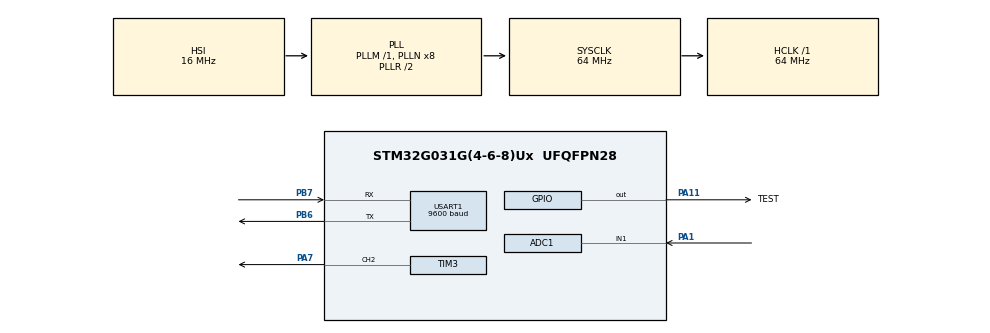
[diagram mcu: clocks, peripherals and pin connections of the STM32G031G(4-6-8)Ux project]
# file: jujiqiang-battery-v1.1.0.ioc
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Mcu.Family=STM32G0
NVIC.TIM14_IRQn=true\:0\:0\:false\:false\:true\:true\:true
RCC.CortexFreq_Value=64000000
ADC1.Rank-0\#ChannelRegularConversion=1
Dma.TIM3_CH2.0.Mode=DMA_NORMAL
PA11\ [PA9].GPIO_Label=TEST
USART1.BaudRate=9600
PA14-BOOT0.Mode=Serial_Wire
Dma.TIM3_CH2.0.PeriphInc=DMA_PINC_DISABLE
RCC.EXTERNAL_CLOCK_VALUE=12288000
Dma.TIM3_CH2.0.Instance=DMA1_Channel1
Dma.TIM3_CH2.0.EventEnable=DISABLE
RCC.SYSCLKSource=RCC_SYSCLKSOURCE_PLLCLK
ProjectManager.StackSize=0x400
Dma.TIM3_CH2.0.Direction=DMA_MEMORY_TO_PERIPH
USART1.VirtualMode-Asynchronous=VM_ASYNC
PA13.Signal=SYS_SWDIO
Dma.TIM3_CH2.0.SyncPolarity=HAL_DMAMUX_SYNC_NO_EVENT
ProjectManager.TargetToolchain=STM32CubeIDE
Dma.TIM3_CH2.0.PeriphDataAlignment=DMA_PDATAALIGN_HALFWORD
RCC.HCLKFreq_Value=64000000
TIM3.Period=79
PB6.Signal=USART1_TX
PA11\ [PA9].GPIO_PuPd=GPIO_PULLUP
PB6.Mode=Asynchronous
RCC.LSE_VALUE=32768
PA1.Signal=ADC1_IN1
PA7.GPIO_PuPd=GPIO_PULLUP
RCC.AHBFreq_Value=64000000
PA14-BOOT0.Signal=SYS_SWCLK
ADC1.Channel-0\#ChannelRegularConversion=ADC_CHANNEL_1
SH.S_TIM3_CH2.0=TIM3_CH2,PWM Generation2 CH2
RCC.HSE_VALUE=8000000
board=custom
RCC.VCOOutputFreq_Value=128000000
TIM14.Period=99
PA7.GPIO_Speed=GPIO_SPEED_FREQ_VERY_HIGH
Dma.TIM3_CH2.0.SyncSignalID=NONE
PA1.Mode=IN1
Dma.TIM3_CH2.0.Priority=DMA_PRIORITY_MEDIUM
Dma.TIM3_CH2.0.MemInc=DMA_MINC_ENABLE
RCC.ADCFreq_Value=64000000
Dma.TIM3_CH2.0.SignalID=NONE
PB7.Signal=USART1_RX
PA13.Mode=Serial_Wire
PA11\ [PA9].Signal=GPIO_Output
Mcu.Name=STM32G031G(4-6-8)Ux
ADC1.SamplingTime-0\#ChannelRegularConversion=ADC_SAMPLINGTIME_COMMON_1
TIM14.Prescaler=639
ADC1.SelectedChannel=ADC_CHANNEL_1
RCC.SYSCLKFreq_VALUE=64000000
Mcu.Package=UFQFPN28
ADC1.master=1
PB7.Mode=Asynchronous
ProjectManager.HeapSize=0x200
Dma.TIM3_CH2.0.MemDataAlignment=DMA_MDATAALIGN_HALFWORD
RCC.HSI_VALUE=16000000
ADC1.NbrOfConversionFlag=1
Dma.TIM3_CH2.0.Polarity=HAL_DMAMUX_REQ_GEN_RISING
Dma.TIM3_CH2.0.SyncRequestNumber=1
TIM3.Channel-PWM\ Generation2\ CH2=TIM_CHANNEL_2
VP_TIM14_VS_ClockSourceINT.Mode=Enable_Timer
Dma.TIM3_CH2.0.RequestNumber=1
NVIC.DMA1_Channel1_IRQn=true\:0\:0\:false\:false\:true\:false\:true
NVIC.USART1_IRQn=true\:0\:0\:false\:false\:true\:true\:true
Dma.Request0=TIM3_CH2
VP_TIM3_VS_ClockSourceINT.Mode=Internal
Dma.TIM3_CH2.0.SyncEnable=DISABLE
PA7.Signal=S_TIM3_CH2

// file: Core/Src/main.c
/* USER CODE BEGIN Header */
/**
  ******************************************************************************
  * @file           : main.c
  * @brief          : Main program body
  ******************************************************************************
  * @attention
  *
  * <h2><center>&copy; Copyright (c) 2021 STMicroelectronics.
  * All rights reserved.</center></h2>
  *
  * This software component is licensed by ST under BSD 3-Clause license,
  * the "License"; You may not use this file except in compliance with the
  * License. You may obtain a copy of the License at:
  *                        opensource.org/licenses/BSD-3-Clause
  *
  ******************************************************************************
  */
/* USER CODE END Header */
#include "main.h"
#include "adc.h"
#include "dma.h"
#include "tim.h"
#include "usart.h"
#include "gpio.h"

/* USER CODE BEGIN Includes */

#include "stdio.h"
#include "S1_main.h"
/* USER CODE END Includes */

void SystemClock_Config(void);

int main(void)
{

  /* MCU Configuration--------------------------------------------------------*/

  /* Reset of all peripherals, Initializes the Flash interface and the Systick. */
  HAL_Init();

  /* Configure the system clock */
  SystemClock_Config();

  /* Initialize all configured peripherals */
  MX_GPIO_Init();
  MX_DMA_Init();
  MX_TIM3_Init();
  MX_ADC1_Init();
  MX_TIM14_Init();
  MX_USART1_UART_Init();
  /* USER CODE BEGIN 2 */
  setup();
  /* USER CODE END 2 */

  /* Infinite loop */
  while (1)
  {

    /* USER CODE BEGIN 3 */

	loop();

  }
  /* USER CODE END 3 */
}

void SystemClock_Config(void)
{
  RCC_OscInitTypeDef RCC_OscInitStruct = {0};
  RCC_ClkInitTypeDef RCC_ClkInitStruct = {0};
  RCC_PeriphCLKInitTypeDef PeriphClkInit = {0};

  /** Configure the main internal regulator output voltage
  */
  HAL_PWREx_ControlVoltageScaling(PWR_REGULATOR_VOLTAGE_SCALE1);
  /** Initializes the RCC Oscillators according to the specified parameters
  * in the RCC_OscInitTypeDef structure.
  */
  RCC_OscInitStruct.OscillatorType = RCC_OSCILLATORTYPE_HSI;
  RCC_OscInitStruct.HSIState = RCC_HSI_ON;
  RCC_OscInitStruct.HSIDiv = RCC_HSI_DIV1;
  RCC_OscInitStruct.HSICalibrationValue = RCC_HSICALIBRATION_DEFAULT;
  RCC_OscInitStruct.PLL.PLLState = RCC_PLL_ON;
  RCC_OscInitStruct.PLL.PLLSource = RCC_PLLSOURCE_HSI;
  RCC_OscInitStruct.PLL.PLLM = RCC_PLLM_DIV1;
  RCC_OscInitStruct.PLL.PLLN = 8;
  RCC_OscInitStruct.PLL.PLLP = RCC_PLLP_DIV2;
  RCC_OscInitStruct.PLL.PLLQ = RCC_PLLQ_DIV2;
  RCC_OscInitStruct.PLL.PLLR = RCC_PLLR_DIV2;
  if (HAL_RCC_OscConfig(&RCC_OscInitStruct) != HAL_OK)
  {
    Error_Handler();
  }
  /** Initializes the CPU, AHB and APB buses clocks
  */
  RCC_ClkInitStruct.ClockType = RCC_CLOCKTYPE_HCLK|RCC_CLOCKTYPE_SYSCLK
                              |RCC_CLOCKTYPE_PCLK1;
  RCC_ClkInitStruct.SYSCLKSource = RCC_SYSCLKSOURCE_PLLCLK;
  RCC_ClkInitStruct.AHBCLKDivider = RCC_SYSCLK_DIV1;
  RCC_ClkInitStruct.APB1CLKDivider = RCC_HCLK_DIV1;

  if (HAL_RCC_ClockConfig(&RCC_ClkInitStruct, FLASH_LATENCY_2) != HAL_OK)
  {
    Error_Handler();
  }
  /** Initializes the peripherals clocks
  */
  PeriphClkInit.PeriphClockSelection = RCC_PERIPHCLK_USART1|RCC_PERIPHCLK_ADC;
  PeriphClkInit.Usart1ClockSelection = RCC_USART1CLKSOURCE_PCLK1;
  PeriphClkInit.AdcClockSelection = RCC_ADCCLKSOURCE_SYSCLK;
  if (HAL_RCCEx_PeriphCLKConfig(&PeriphClkInit) != HAL_OK)
  {
    Error_Handler();
  }
}

void Error_Handler(void)
{
  __disable_irq();
  while (1)
  {
  }
}

/************************ (C) COPYRIGHT STMicroelectronics *****END OF FILE****/
